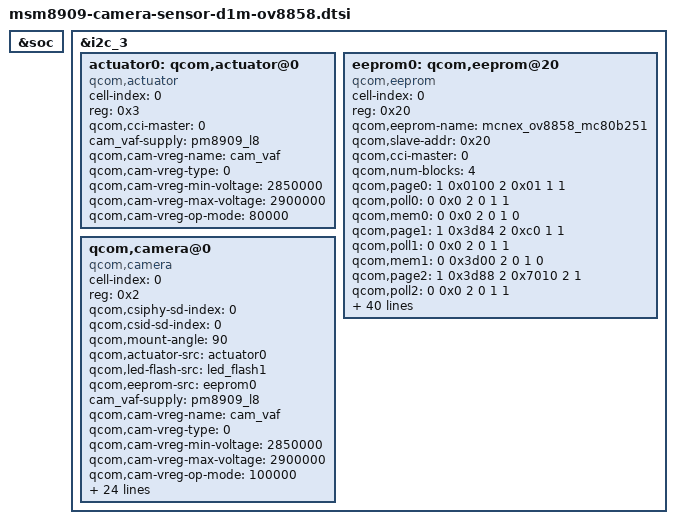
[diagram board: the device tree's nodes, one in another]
/*
 * Copyright (c) 2014, The Linux Foundation. All rights reserved.
 *
 * This program is free software; you can redistribute it and/or modify
 * it under the terms of the GNU General Public License version 2 and
 * only version 2 as published by the Free Software Foundation.
 *
 * This program is distributed in the hope that it will be useful,
 * but WITHOUT ANY WARRANTY; without even the implied warranty of
 * MERCHANTABILITY or FITNESS FOR A PARTICULAR PURPOSE.  See the
 * GNU General Public License for more details.
 */

&soc {
};

&i2c_3 {
	actuator0: qcom,actuator@0 {
		cell-index = <0>;
		reg = <0x3>;
		compatible = "qcom,actuator";
		qcom,cci-master = <0>;
		cam_vaf-supply = <&pm8909_l8>;
		qcom,cam-vreg-name = "cam_vaf";
		qcom,cam-vreg-type = <0>;
		qcom,cam-vreg-min-voltage = <2850000>;
		qcom,cam-vreg-max-voltage = <2900000>;
		qcom,cam-vreg-op-mode = <80000>;
		status = "ok";
	};

/*fihtdc,DerekCWWu, 20150519, modify for OV8858 R2A,start*/
	eeprom0: qcom,eeprom@20{
		cell-index = <0>;
		reg = <0x20>;
		qcom,eeprom-name = "mcnex_ov8858_mc80b251";
		compatible = "qcom,eeprom";
		qcom,slave-addr = <0x20>;
		qcom,cci-master = <0>;
		qcom,num-blocks = <4>;

		qcom,page0 = <1 0x0100 2 0x01 1 1>;
		qcom,poll0 = <0 0x0 2 0 1 1>;
		qcom,mem0 = <0 0x0 2 0 1 0>;
		qcom,page1 = <1 0x3d84 2 0xc0 1 1>;
		qcom,poll1 = <0 0x0 2 0 1 1>;
		qcom,mem1 = <0 0x3d00 2 0 1 0>;
		qcom,page2 = <1 0x3d88 2 0x7010 2 1>;
		qcom,poll2 = <0 0x0 2 0 1 1>;
		qcom,mem2 = <0 0x3d00 2 0 1 0>;
		qcom,page3 = <1 0x3d8A 2 0x720a 2 1>;
		qcom,pageen3 = <1 0x3d81 2 0x01 1 10>;
		qcom,poll3 = <0 0x0 2 0 1 1>;
		qcom,mem3 = <507 0x7010 2 0 1 1>;

		cam_vaf-supply = <&pm8909_l8>;
		qcom,cam-vreg-name = "cam_vaf";
		qcom,cam-vreg-type = <0>;
		qcom,cam-vreg-min-voltage = <2850000>;
		qcom,cam-vreg-max-voltage = <2900000>;
		qcom,cam-vreg-op-mode = <100000>;
		qcom,enable_pinctrl;
		pinctrl-names = "cam_default", "cam_suspend";
		pinctrl-0 = <&cam_sensor_mclk0_default
					&cam_sensor_rear_default>;
		pinctrl-1 = <&cam_sensor_mclk0_sleep &cam_sensor_rear_sleep>;
		gpios = <&msm_gpio 26 0>,
			<&msm_gpio 35 0>,
			<&msm_gpio 34 0>,
			<&msm_gpio 8 0>,
			<&msm_gpio 9 0>,
			<&msm_gpio 58 0>;
		qcom,gpio-reset = <1>;
		qcom,gpio-standby = <2>;
		qcom,gpio-vana = <3>;
		qcom,gpio-vio = <4>;
		qcom,gpio-vdig = <5>;
		qcom,gpio-req-tbl-num = <0 1 2 3 4 5>;
		qcom,gpio-req-tbl-flags = <1 0 0 0 0 0>;
		qcom,gpio-req-tbl-label = "CAMIF_MCLK",
			"CAM_RESET1",
			"CAM_STANDBY",
			"CAM_VANA",
			"CAM_VIO",
			"CAM_VDIG";
		qcom,cam-power-seq-type = "sensor_vreg","sensor_gpio",
			"sensor_gpio","sensor_gpio",
			"sensor_gpio","sensor_gpio",
			"sensor_clk";
		qcom,cam-power-seq-val = "cam_vaf","sensor_gpio_vio",
			"sensor_gpio_vana","sensor_gpio_vdig",
			"sensor_gpio_standby","sensor_gpio_reset",
			"sensor_cam_mclk" ;
		qcom,cam-power-seq-cfg-val = <0 1 1 1 1 1 23880000>;
		qcom,cam-power-seq-delay = <1 10 10 10 10 10 5>;
		clocks = <&clock_gcc clk_mclk0_clk_src>,
			<&clock_gcc clk_gcc_camss_mclk0_clk>;
		clock-names = "cam_src_clk", "cam_clk";
		status = "ok";
	};
/*fihtdc,DerekCWWu, 20150519, modify for OV8858 R2A,end*/

	qcom,camera@0 {
		cell-index = <0>;
		compatible = "qcom,camera";
		reg = <0x2>;
		qcom,csiphy-sd-index = <0>;
		qcom,csid-sd-index = <0>;
		qcom,mount-angle = <90>;
		qcom,actuator-src = <&actuator0>;
		qcom,led-flash-src = <&led_flash1>;
		qcom,eeprom-src = <&eeprom0>;
		cam_vaf-supply = <&pm8909_l8>;
		qcom,cam-vreg-name = "cam_vaf";
		qcom,cam-vreg-type = <0>;
		qcom,cam-vreg-min-voltage = <2850000>;
		qcom,cam-vreg-max-voltage = <2900000>;
		qcom,cam-vreg-op-mode = <100000>;
		pinctrl-names = "cam_default", "cam_suspend";
		pinctrl-0 = <&cam_sensor_mclk0_default
				&cam_sensor_rear_default>;
		pinctrl-1 = <&cam_sensor_mclk0_sleep &cam_sensor_rear_sleep>;
		gpios = <&msm_gpio 26 0>,
			<&msm_gpio 35 0>,
			<&msm_gpio 34 0>,
			<&msm_gpio 8 0>,
			<&msm_gpio 9 0>,
			<&msm_gpio 58 0>,
			<&msm_gpio 28 0>,
			<&msm_gpio 21 0>;
		qcom,gpio-reset = <1>;
		qcom,gpio-standby = <2>;
		qcom,gpio-vana = <3>;
		qcom,gpio-vio = <4>;
		qcom,gpio-vdig = <5>;
		qcom,gpio-custom1 = <6>;
		qcom,gpio-custom2 = <7>;
		qcom,gpio-req-tbl-num = <0 1 2 3 4 5 6 7>;
		qcom,gpio-req-tbl-flags = <1 0 0 0 0 0 0 0>;
		qcom,gpio-req-tbl-label = "CAMIF_MCLK",
			"CAM_RESET1",
			"CAM_STANDBY",
			"CAM_VANA",
			"CAM_VIO",
			"CAM_VDIG",
			"CAM_MIPI_SEL",
			"CAM_MIPI_OE";
		qcom,sensor-position = <0>;
		qcom,sensor-mode = <0>;
		qcom,cci-master = <0>;
		clocks = <&clock_gcc clk_mclk0_clk_src>,
				<&clock_gcc clk_gcc_camss_mclk0_clk>;
		clock-names = "cam_src_clk", "cam_clk";
		status = "ok";
	};
};
